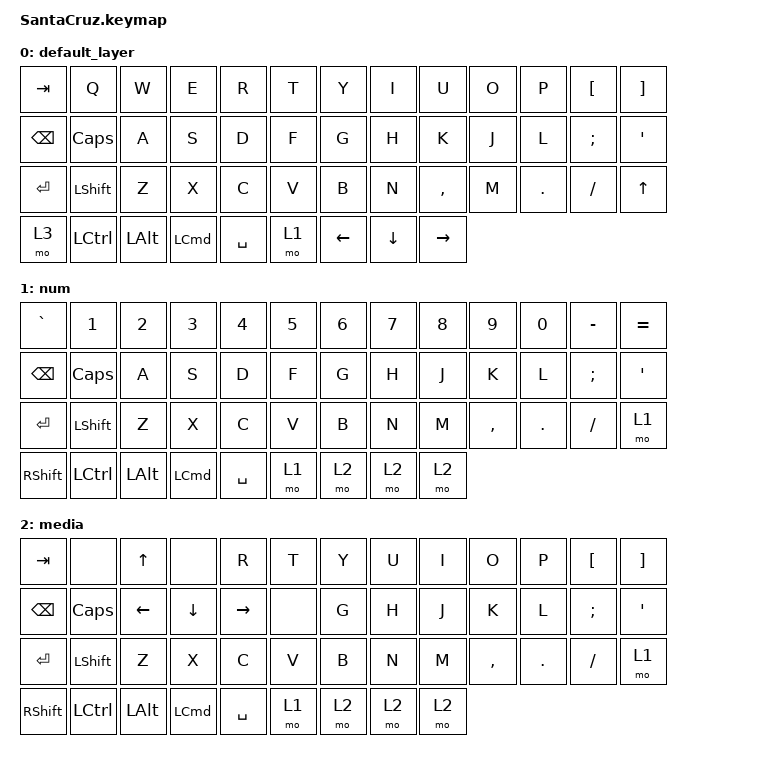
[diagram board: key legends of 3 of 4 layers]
/*
 * Copyright (c) 2020 The ZMK Contributors
 *
 * SPDX-License-Identifier: MIT
 */

#include <behaviors.dtsi>
#include <dt-bindings/zmk/keys.h>

/ {
    keymap {
        compatible = "zmk,keymap";

        default_layer {
            // ----------------------------------------------------------------------------------------------------------
            // |  ESC  |  1   |  2   |  3   |  4   |  5   |-------|-------|   6   |  7    |  8   |  9   |   0   | BSPC  |
            // |  TAB  |  Q   |  W   |  E   |  R   |  T   |-------|-------|   Y   |  U    |  I   |  O   |   P   |  \    |
            // | SHIFT |  A   |  S   |  D   |  F   |  G   |-------|-------|   H   |  J    |  K   |  L   |   ;   |  '    |
            // | CTRL  |  Z   |  X   |  C   |  V   |  B   |-------|-------|   N   |  M    |  ,   |  .   |   /   | ENTER |
            // |-------|ADJUST| LCTL | LALT | LGUI | LOWR | SPACE | SPACE |  RAIS | LEFT | DOWN | UARW  | RARW  |-------|

            bindings = <
&kp TAB    &kp Q             &kp W         &kp E             &kp R      &kp T  &kp Y           &kp I           &kp U            &kp O  &kp P       &kp LEFT_BRACKET  &kp RIGHT_BRACKET
&kp BSPC   &kp CAPS          &kp A         &kp S             &kp D      &kp F  &kp G           &kp H           &kp K            &kp J  &kp L       &kp SEMICOLON     &kp SQT
&kp ENTER  &kp LSHFT         &kp Z         &kp X             &kp C      &kp V  &kp B           &kp N           &kp COMMA        &kp M  &kp PERIOD  &kp SLASH         &kp UP_ARROW
&mo 3      &kp LEFT_CONTROL  &kp LEFT_ALT  &kp LEFT_COMMAND  &kp SPACE  &mo 1  &kp LEFT_ARROW  &kp DOWN_ARROW  &kp RIGHT_ARROW
            >;
        };

        num {
            // ----------------------------------------------------------------------------------------------------------
            // |  ESC  |  F2  |  F3  |  F4  |  F5  |  F6  |-------|-------|   F7  |  F8   |  F9  | F10  |  F11  |  F12  |
            // |   ~   |  !   |  @   |  #   |  $   |  %   |-------|-------|   ^   |   &   |  *   |  (   |   )   |  DEL  |
            // |       |  F1  |  F2  |  F3  |  F4  |  F5  |-------|-------|   F6  |   _   |  +   |  {   |   }   |   |   |
            // |       |  F7  |  F8  |  F9  |  F10 |  F11 |-------|-------|   F12 | LS(#) |LS(|) |      |       |       |
            // |-------|      |      |      |      |      |       |       |       | NEXT  | Vol- | Vol+ | PLAY  |-------|

            bindings = <
&kp GRAVE        &kp NUMBER_1      &kp NUMBER_2  &kp NUMBER_3      &kp NUMBER_4  &kp NUMBER_5  &kp NUMBER_6  &kp NUMBER_7  &kp NUMBER_8  &kp NUMBER_9  &kp NUMBER_0  &kp MINUS      &kp EQUAL
&kp BSPC         &kp CAPS          &kp A         &kp S             &kp D         &kp F         &kp G         &kp H         &kp J         &kp K         &kp L         &kp SEMICOLON  &kp SQT
&kp ENTER        &kp LSHFT         &kp Z         &kp X             &kp C         &kp V         &kp B         &kp N         &kp M         &kp COMMA     &kp PERIOD    &kp SLASH      &mo 1
&kp RIGHT_SHIFT  &kp LEFT_CONTROL  &kp LEFT_ALT  &kp LEFT_COMMAND  &kp SPACE     &mo 1         &mo 2         &mo 2         &mo 2
            >;
        };

        media {
            bindings = <
&kp TAB          &none             &kp UP_ARROW  &none             &kp R      &kp T  &kp Y  &kp U  &kp I  &kp O      &kp P       &kp LEFT_BRACKET  &kp RIGHT_BRACKET
&kp BSPC         &kp CAPS          &kp LEFT      &kp DOWN_ARROW    &kp RIGHT  &none  &kp G  &kp H  &kp J  &kp K      &kp L       &kp SEMICOLON     &kp SQT
&kp ENTER        &kp LSHFT         &kp Z         &kp X             &kp C      &kp V  &kp B  &kp N  &kp M  &kp COMMA  &kp PERIOD  &kp SLASH         &mo 1
&kp RIGHT_SHIFT  &kp LEFT_CONTROL  &kp LEFT_ALT  &kp LEFT_COMMAND  &kp SPACE  &mo 1  &mo 2  &mo 2  &mo 2
            >;
        };

        layer_3 {
            bindings = <
&trans  &trans  &trans  &trans  &trans  &trans  &trans  &trans  &kp C_PREV  &kp C_PAUSE  &kp C_NEXT  &kp C_VOLUME_DOWN  &kp C_VOLUME_UP
&trans  &trans  &trans  &trans  &trans  &trans  &trans  &trans  &trans      &trans       &trans      &trans             &trans
&trans  &trans  &trans  &trans  &trans  &trans  &trans  &trans  &trans      &trans       &trans      &trans             &trans
&trans  &trans  &trans  &trans  &trans  &trans  &trans  &trans  &trans      &trans       &trans      &trans             &trans
            >;
        };
    };
};
